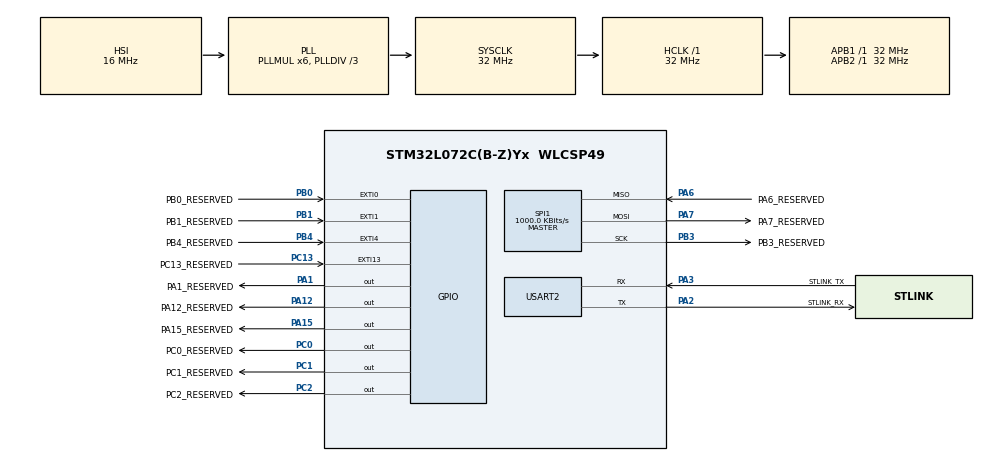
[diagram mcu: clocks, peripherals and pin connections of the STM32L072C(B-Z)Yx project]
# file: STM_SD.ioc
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Mcu.Family=STM32L0
Mcu.Name=STM32L072C(B-Z)Yx
Mcu.Package=WLCSP49
NVIC.EXTI0_1_IRQn=true\:0\:0\:false\:false\:true\:true\:true
NVIC.EXTI4_15_IRQn=true\:0\:0\:false\:false\:true\:true\:true
NVIC.RTC_IRQn=true\:0\:0\:false\:false\:true\:true\:true
NVIC.USART2_IRQn=true\:0\:0\:false\:false\:true\:true\:true
PA1.GPIO_Label=PA1_RESERVED
PA1.GPIO_Speed=GPIO_SPEED_FREQ_HIGH
PA1.PinState=GPIO_PIN_RESET
PA1.Signal=GPIO_Output
PA12.GPIO_Label=PA12_RESERVED
PA12.GPIO_Speed=GPIO_SPEED_FREQ_HIGH
PA12.Signal=GPIO_Output
PA15.GPIO_Label=PA15_RESERVED
PA15.GPIO_Speed=GPIO_SPEED_FREQ_HIGH
PA15.Signal=GPIO_Output
PA2.GPIO_Label=STLINK_RX
PA2.Mode=Asynchronous
PA2.Signal=USART2_TX
PA3.GPIO_Label=STLINK_TX
PA3.Mode=Asynchronous
PA3.Signal=USART2_RX
PA6.GPIO_Label=PA6_RESERVED
PA6.Mode=Full_Duplex_Master
PA6.Signal=SPI1_MISO
PA7.GPIO_Label=PA7_RESERVED
PA7.Mode=Full_Duplex_Master
PA7.Signal=SPI1_MOSI
PB0.GPIO_Label=PB0_RESERVED
PB0.Signal=GPXTI0
PB1.GPIO_Label=PB1_RESERVED
PB1.Signal=GPXTI1
PB3.GPIO_Label=PB3_RESERVED
PB3.Mode=Full_Duplex_Master
PB3.Signal=SPI1_SCK
PB4.GPIO_Label=PB4_RESERVED
PB4.Signal=GPXTI4
PC0.GPIO_Label=PC0_RESERVED
PC0.GPIO_Speed=GPIO_SPEED_FREQ_HIGH
PC0.Signal=GPIO_Output
PC1.GPIO_Label=PC1_RESERVED
PC1.GPIO_Speed=GPIO_SPEED_FREQ_HIGH
PC1.Signal=GPIO_Output
PC13.GPIO_Label=PC13_RESERVED
PC13.Signal=GPXTI13
PC2.GPIO_Label=PC2_RESERVED
PC2.GPIO_Speed=GPIO_SPEED_FREQ_HIGH
PC2.Signal=GPIO_Output
PH0-OSC_IN.Signal=RCC_OSC_IN
PH1-OSC_OUT.Signal=RCC_OSC_OUT
ProjectManager.HeapSize=0x2000
ProjectManager.StackSize=0x4000
ProjectManager.TargetToolchain=MDK-ARM V5
RCC.AHBFreq_Value=32000000
RCC.APB1Freq_Value=32000000
RCC.APB1TimFreq_Value=32000000
RCC.APB2Freq_Value=32000000
RCC.APB2TimFreq_Value=32000000
RCC.HCLKFreq_Value=32000000
RCC.HSE_VALUE=8000000
RCC.HSI16_VALUE=16000000
RCC.HSI48_VALUE=48000000
RCC.HSI_VALUE=16000000
RCC.LSE_VALUE=32768
RCC.MSI_VALUE=2097000
RCC.PLLDIV=RCC_PLLDIV_3
RCC.PLLMUL=RCC_PLLMUL_6
RCC.SYSCLKFreq_VALUE=32000000
RCC.SYSCLKSource=RCC_SYSCLKSOURCE_PLLCLK
RCC.VCOOutputFreq_Value=96000000
RTC.Alarm-Alarm\ A=RTC_ALARM_A
RTC.AlarmSubSecondMask-Alarm\ A=RTC_ALARMSUBSECONDMASK_NONE
RTC.AsynchPrediv=31
RTC.Format=RTC_FORMAT_BIN
RTC.SynchPrediv=1023
SPI1.BaudRatePrescaler=SPI_BAUDRATEPRESCALER_32
SPI1.CalculateBaudRate=1000.0 KBits/s
SPI1.Direction=SPI_DIRECTION_2LINES
SPI1.Mode=SPI_MODE_MASTER
SPI1.VirtualType=VM_MASTER
USART2.VirtualMode-Asynchronous=VM_ASYNC
VP_FATFS_VS_Generic.Mode=User_defined
VP_RTC_VS_RTC_Activate.Mode=RTC_Enabled
VP_RTC_VS_RTC_Alarm_A_Intern.Mode=Alarm A
VP_RTC_VS_RTC_Calendar.Mode=RTC_Calendar
board=B-L072Z-LRWAN1

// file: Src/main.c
/* USER CODE BEGIN Header */
/**
  ******************************************************************************
  * @file           : main.c
  * @brief          : Main program body
  ******************************************************************************
  * @attention
  *
  * <h2><center>&copy; Copyright (c) 2019 STMicroelectronics.
  * All rights reserved.</center></h2>
  *
  * This software component is licensed by ST under Ultimate Liberty license
  * SLA0044, the "License"; You may not use this file except in compliance with
  * the License. You may obtain a copy of the License at:
  *                             www.st.com/SLA0044
  *
  ******************************************************************************
  */
/* USER CODE END Header */

#include "main.h"
#include "fatfs.h"

RTC_HandleTypeDef hrtc;

SPI_HandleTypeDef hspi1;

UART_HandleTypeDef huart2;

void SystemClock_Config(void);
static void MX_GPIO_Init(void);
static void MX_RTC_Init(void);
static void MX_SPI1_Init(void);
static void MX_USART2_UART_Init(void);

int main(void)
{

  /* MCU Configuration--------------------------------------------------------*/

  /* Reset of all peripherals, Initializes the Flash interface and the Systick. */
  HAL_Init();

  /* Configure the system clock */
  SystemClock_Config();

  /* Initialize all configured peripherals */
  MX_GPIO_Init();
  MX_RTC_Init();
  MX_SPI1_Init();
  MX_USART2_UART_Init();
  MX_FATFS_Init();
  /* USER CODE BEGIN 2 */
 FATFS myfile;
 FIL fats;
 UINT testByte;
  f_mount(&myfile, USERPath , 1);
  char mypath[] = "TEST.TXT\0";
	f_open(&fats, mypath, FA_WRITE| FA_CREATE_ALWAYS);
	char mydata[] = "Hello from the STM32";
	f_write(&fats , mydata, sizeof(mydata), &testByte);
	f_close(&fats);
  /* USER CODE END 2 */

  /* Infinite loop */
  while (1)
  {

  }
}

void SystemClock_Config(void)
{
  RCC_OscInitTypeDef RCC_OscInitStruct = {0};
  RCC_ClkInitTypeDef RCC_ClkInitStruct = {0};
  RCC_PeriphCLKInitTypeDef PeriphClkInit = {0};

  /** Configure the main internal regulator output voltage
  */
  __HAL_PWR_VOLTAGESCALING_CONFIG(PWR_REGULATOR_VOLTAGE_SCALE1);
  /** Initializes the CPU, AHB and APB busses clocks
  */
  RCC_OscInitStruct.OscillatorType = RCC_OSCILLATORTYPE_HSI|RCC_OSCILLATORTYPE_LSI;
  RCC_OscInitStruct.HSIState = RCC_HSI_ON;
  RCC_OscInitStruct.HSICalibrationValue = RCC_HSICALIBRATION_DEFAULT;
  RCC_OscInitStruct.LSIState = RCC_LSI_ON;
  RCC_OscInitStruct.PLL.PLLState = RCC_PLL_ON;
  RCC_OscInitStruct.PLL.PLLSource = RCC_PLLSOURCE_HSI;
  RCC_OscInitStruct.PLL.PLLMUL = RCC_PLLMUL_6;
  RCC_OscInitStruct.PLL.PLLDIV = RCC_PLLDIV_3;
  if (HAL_RCC_OscConfig(&RCC_OscInitStruct) != HAL_OK)
  {
    Error_Handler();
  }
  /** Initializes the CPU, AHB and APB busses clocks
  */
  RCC_ClkInitStruct.ClockType = RCC_CLOCKTYPE_HCLK|RCC_CLOCKTYPE_SYSCLK
                              |RCC_CLOCKTYPE_PCLK1|RCC_CLOCKTYPE_PCLK2;
  RCC_ClkInitStruct.SYSCLKSource = RCC_SYSCLKSOURCE_PLLCLK;
  RCC_ClkInitStruct.AHBCLKDivider = RCC_SYSCLK_DIV1;
  RCC_ClkInitStruct.APB1CLKDivider = RCC_HCLK_DIV1;
  RCC_ClkInitStruct.APB2CLKDivider = RCC_HCLK_DIV1;

  if (HAL_RCC_ClockConfig(&RCC_ClkInitStruct, FLASH_LATENCY_1) != HAL_OK)
  {
    Error_Handler();
  }
  PeriphClkInit.PeriphClockSelection = RCC_PERIPHCLK_USART2|RCC_PERIPHCLK_RTC;
  PeriphClkInit.Usart2ClockSelection = RCC_USART2CLKSOURCE_PCLK1;
  PeriphClkInit.RTCClockSelection = RCC_RTCCLKSOURCE_LSI;
  if (HAL_RCCEx_PeriphCLKConfig(&PeriphClkInit) != HAL_OK)
  {
    Error_Handler();
  }
}

static void MX_RTC_Init(void)
{

  RTC_TimeTypeDef sTime = {0};
  RTC_DateTypeDef sDate = {0};
  RTC_AlarmTypeDef sAlarm = {0};

  /** Initialize RTC Only
  */
  hrtc.Instance = RTC;
  hrtc.Init.HourFormat = RTC_HOURFORMAT_24;
  hrtc.Init.AsynchPrediv = 31;
  hrtc.Init.SynchPrediv = 1023;
  hrtc.Init.OutPut = RTC_OUTPUT_DISABLE;
  hrtc.Init.OutPutRemap = RTC_OUTPUT_REMAP_NONE;
  hrtc.Init.OutPutPolarity = RTC_OUTPUT_POLARITY_HIGH;
  hrtc.Init.OutPutType = RTC_OUTPUT_TYPE_OPENDRAIN;
  if (HAL_RTC_Init(&hrtc) != HAL_OK)
  {
    Error_Handler();
  }

  /** Initialize RTC and set the Time and Date
  */
  sTime.Hours = 0;
  sTime.Minutes = 0;
  sTime.Seconds = 0;
  sTime.DayLightSaving = RTC_DAYLIGHTSAVING_NONE;
  sTime.StoreOperation = RTC_STOREOPERATION_RESET;
  if (HAL_RTC_SetTime(&hrtc, &sTime, RTC_FORMAT_BIN) != HAL_OK)
  {
    Error_Handler();
  }
  sDate.WeekDay = RTC_WEEKDAY_MONDAY;
  sDate.Month = RTC_MONTH_JANUARY;
  sDate.Date = 1;
  sDate.Year = 0;

  if (HAL_RTC_SetDate(&hrtc, &sDate, RTC_FORMAT_BIN) != HAL_OK)
  {
    Error_Handler();
  }
  /** Enable the Alarm A
  */
  sAlarm.AlarmTime.Hours = 0;
  sAlarm.AlarmTime.Minutes = 0;
  sAlarm.AlarmTime.Seconds = 0;
  sAlarm.AlarmTime.SubSeconds = 0;
  sAlarm.AlarmTime.DayLightSaving = RTC_DAYLIGHTSAVING_NONE;
  sAlarm.AlarmTime.StoreOperation = RTC_STOREOPERATION_RESET;
  sAlarm.AlarmMask = RTC_ALARMMASK_NONE;
  sAlarm.AlarmSubSecondMask = RTC_ALARMSUBSECONDMASK_NONE;
  sAlarm.AlarmDateWeekDaySel = RTC_ALARMDATEWEEKDAYSEL_DATE;
  sAlarm.AlarmDateWeekDay = 1;
  sAlarm.Alarm = RTC_ALARM_A;
  if (HAL_RTC_SetAlarm_IT(&hrtc, &sAlarm, RTC_FORMAT_BIN) != HAL_OK)
  {
    Error_Handler();
  }

}

static void MX_SPI1_Init(void)
{

  /* SPI1 parameter configuration*/
  hspi1.Instance = SPI1;
  hspi1.Init.Mode = SPI_MODE_MASTER;
  hspi1.Init.Direction = SPI_DIRECTION_2LINES;
  hspi1.Init.DataSize = SPI_DATASIZE_8BIT;
  hspi1.Init.CLKPolarity = SPI_POLARITY_LOW;
  hspi1.Init.CLKPhase = SPI_PHASE_1EDGE;
  hspi1.Init.NSS = SPI_NSS_SOFT;
  hspi1.Init.BaudRatePrescaler = SPI_BAUDRATEPRESCALER_32;
  hspi1.Init.FirstBit = SPI_FIRSTBIT_MSB;
  hspi1.Init.TIMode = SPI_TIMODE_DISABLE;
  hspi1.Init.CRCCalculation = SPI_CRCCALCULATION_DISABLE;
  hspi1.Init.CRCPolynomial = 7;
  if (HAL_SPI_Init(&hspi1) != HAL_OK)
  {
    Error_Handler();
  }

}

static void MX_USART2_UART_Init(void)
{

  huart2.Instance = USART2;
  huart2.Init.BaudRate = 115200;
  huart2.Init.WordLength = UART_WORDLENGTH_8B;
  huart2.Init.StopBits = UART_STOPBITS_1;
  huart2.Init.Parity = UART_PARITY_NONE;
  huart2.Init.Mode = UART_MODE_TX_RX;
  huart2.Init.HwFlowCtl = UART_HWCONTROL_NONE;
  huart2.Init.OverSampling = UART_OVERSAMPLING_16;
  huart2.Init.OneBitSampling = UART_ONE_BIT_SAMPLE_DISABLE;
  huart2.AdvancedInit.AdvFeatureInit = UART_ADVFEATURE_NO_INIT;
  if (HAL_UART_Init(&huart2) != HAL_OK)
  {
    Error_Handler();
  }

}

static void MX_GPIO_Init(void)
{
  GPIO_InitTypeDef GPIO_InitStruct = {0};

  /* GPIO Ports Clock Enable */
  __HAL_RCC_GPIOA_CLK_ENABLE();
  __HAL_RCC_GPIOB_CLK_ENABLE();
  __HAL_RCC_GPIOC_CLK_ENABLE();
  __HAL_RCC_GPIOH_CLK_ENABLE();

  /*Configure GPIO pin Output Level */
  HAL_GPIO_WritePin(GPIOA, PA15_RESERVED_Pin|PA12_RESERVED_Pin|PA1_RESERVED_Pin, GPIO_PIN_RESET);

  /*Configure GPIO pin Output Level */
  HAL_GPIO_WritePin(GPIOC, PC1_RESERVED_Pin|PC0_RESERVED_Pin|PC2_RESERVED_Pin, GPIO_PIN_RESET);

  /*Configure GPIO pins : PA15_RESERVED_Pin PA12_RESERVED_Pin PA1_RESERVED_Pin */
  GPIO_InitStruct.Pin = PA15_RESERVED_Pin|PA12_RESERVED_Pin|PA1_RESERVED_Pin;
  GPIO_InitStruct.Mode = GPIO_MODE_OUTPUT_PP;
  GPIO_InitStruct.Pull = GPIO_NOPULL;
  GPIO_InitStruct.Speed = GPIO_SPEED_FREQ_HIGH;
  HAL_GPIO_Init(GPIOA, &GPIO_InitStruct);

  /*Configure GPIO pins : PB4_RESERVED_Pin PB1_RESERVED_Pin PB0_RESERVED_Pin */
  GPIO_InitStruct.Pin = PB4_RESERVED_Pin|PB1_RESERVED_Pin|PB0_RESERVED_Pin;
  GPIO_InitStruct.Mode = GPIO_MODE_IT_RISING;
  GPIO_InitStruct.Pull = GPIO_NOPULL;
  HAL_GPIO_Init(GPIOB, &GPIO_InitStruct);

  /*Configure GPIO pin : PC13_RESERVED_Pin */
  GPIO_InitStruct.Pin = PC13_RESERVED_Pin;
  GPIO_InitStruct.Mode = GPIO_MODE_IT_RISING;
  GPIO_InitStruct.Pull = GPIO_NOPULL;
  HAL_GPIO_Init(PC13_RESERVED_GPIO_Port, &GPIO_InitStruct);

  /*Configure GPIO pins : PC1_RESERVED_Pin PC0_RESERVED_Pin PC2_RESERVED_Pin */
  GPIO_InitStruct.Pin = PC1_RESERVED_Pin|PC0_RESERVED_Pin|PC2_RESERVED_Pin;
  GPIO_InitStruct.Mode = GPIO_MODE_OUTPUT_PP;
  GPIO_InitStruct.Pull = GPIO_NOPULL;
  GPIO_InitStruct.Speed = GPIO_SPEED_FREQ_HIGH;
  HAL_GPIO_Init(GPIOC, &GPIO_InitStruct);

  /* EXTI interrupt init*/
  HAL_NVIC_SetPriority(EXTI0_1_IRQn, 0, 0);
  HAL_NVIC_EnableIRQ(EXTI0_1_IRQn);

  HAL_NVIC_SetPriority(EXTI4_15_IRQn, 0, 0);
  HAL_NVIC_EnableIRQ(EXTI4_15_IRQn);

}

void Error_Handler(void)
{
}

/************************ (C) COPYRIGHT STMicroelectronics *****END OF FILE****/
